# CY8C3246PVI_147 register map
File version: 0.1
CY8C32
Registers are 8-bit, read-write, no defined reset value unless marked. A register's access mark holds for its fields unless they carry their own. Offsets are from the block's base; lines under a group give offsets from that group; [hi:lo] are bit positions; {n}, {i} and the like mark numbered series; 'fields as' and 'values as' point back to an identical list; <NAME> marks a mode.

## Memory map
0x00004382 RTC size 0xF
0x00004394 USBUART size 0x1D0A — USBFS
0x000043AA ADC size 0x17E0
0x0000640A USB_Blink_TI size 0x92
0x0000640C Flash_Blink_TI size 0x92
0x0000640E EEPROM_Blink_TI size 0x92

## RTC
Base 0x00004382
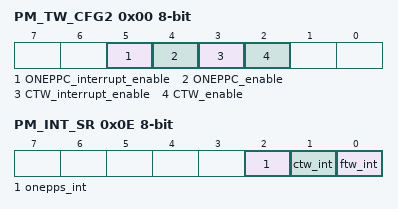
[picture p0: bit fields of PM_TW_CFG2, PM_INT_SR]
0x00 PM_TW_CFG2 — Power timers enable and interrupt enable configuration register
  [5] ONEPPC_interrupt_enable — When set and one pulse-per-second is enabled, an interrupt is issued when the pulse occurs
    1=Enabled (The ONEPPC interrupt is issued. Only if ONEPPC is enabled.); 0=Disabled (No ONEPPC interrupt is issued.)
  [4] ONEPPC_enable
    1=Enabled (The ONEPPC is enabled.); 0=Disabled (The ONEPPC is disabled.)
  [3] CTW_interrupt_enable — An interrupt issue when the CTW reaches the selected interval
    1=Enabled (The CTW interrupt is issued. Only if CTW is enabled.); 0=Disabled (No CTW interrupt is issued.)
  [2] CTW_enable
    1=Enabled (The CTW is enabled.); 0=Disabled (The CTW is disabled.)
0x0E PM_INT_SR — Power Manager Interrupt Status Register
  [2] onepps_int — When set, a onepps event has occured.
  [1] ctw_int — When set, a limited active ready event has occured
  [0] ftw_int — When set, a fast timewheel event has occured

## Flash_Blink_TI
Base 0x0000640C
0x00 Flash_Blink_TI_COUNTER 16-bit — UDB.A0 - Current Down Counter Value
0x20 Flash_Blink_TI_PERIOD 16-bit — UDB.D0 - Assigned Period
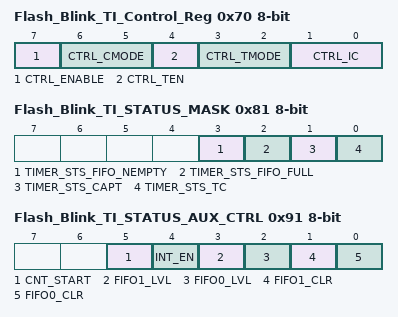
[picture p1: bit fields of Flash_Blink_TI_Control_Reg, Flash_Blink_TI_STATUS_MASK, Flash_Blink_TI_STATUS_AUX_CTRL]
0x70 Flash_Blink_TI_Control_Reg — UDB Control Register - Assigned Control Register Value
  [7] CTRL_ENABLE — Enable the Timer
  [6:5] CTRL_CMODE — Capture Mode
  [4] CTRL_TEN — Trigger Enable Bit
  [3:2] CTRL_TMODE — Trigger Mode
  [1:0] CTRL_IC — Interrupt Count
0x81 Flash_Blink_TI_STATUS_MASK — UDB Status bits Interrupt Mask Enable Register
  [3] TIMER_STS_FIFO_NEMPTY ro — FIFO Empty status
  [2] TIMER_STS_FIFO_FULL ro — FIFO Full Status
  [1] TIMER_STS_CAPT ro — Enables the Interrupt on Capture
  [0] TIMER_STS_TC ro — Enables the Interrupt on TC
0x91 Flash_Blink_TI_STATUS_AUX_CTRL — UDB Auxilliary Control Register
  [5] CNT_START — FIFO0 clear
    0=E_CNT_START0 (Disable counter); 1=E_CNT_START1 (Enable counter)
  [4] INT_EN
    0=E_INT_EN0 (Interrupt disabled); 1=E_INT_EN1 (Interrupt enabled)
  [3] FIFO1_LVL — FIFO level
    0=E_FIFO_LVL_0 (FIFO LVL: input mode: FIFO not full; output mode: FIFO not empty); 1=E_FIFO_LVL_1 (FIFO LVL: input mode: FIFO at least 1/2 empty; output mode: FIFO at least 1/2 full)
  [2] FIFO0_LVL — FIFO level
    values as FIFO1_LVL
  [1] FIFO1_CLR — FIFO1 clear
    0=E_FIFO_CLR_0 (Normal FIFO operation); 1=E_FIFO_CLR_1 (Clear FIFO state)
  [0] FIFO0_CLR — FIFO0 clear
    values as FIFO1_CLR

## USB_Blink_TI
Base 0x0000640A
Registers as Flash_Blink_TI (with Flash_Blink_TI read as USB_Blink_TI), without Flash_Blink_TI_Control_Reg; these are added or differ:
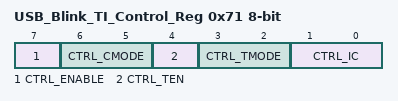
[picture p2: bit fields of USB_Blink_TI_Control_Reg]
0x71 USB_Blink_TI_Control_Reg — UDB Control Register - Assigned Control Register Value
  [7] CTRL_ENABLE — Enable the Timer
  [6:5] CTRL_CMODE — Capture Mode
  [4] CTRL_TEN — Trigger Enable Bit
  [3:2] CTRL_TMODE — Trigger Mode
  [1:0] CTRL_IC — Interrupt Count

## EEPROM_Blink_TI
Base 0x0000640E
Registers as Flash_Blink_TI (with Flash_Blink_TI read as EEPROM_Blink_TI).

## USBUART — USBFS
Base 0x00004394
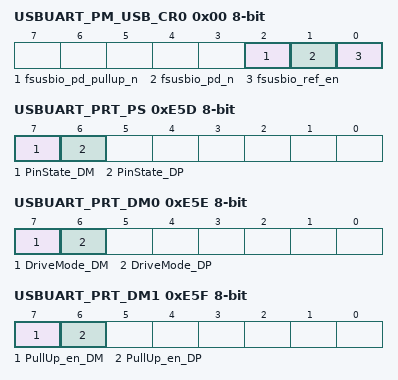
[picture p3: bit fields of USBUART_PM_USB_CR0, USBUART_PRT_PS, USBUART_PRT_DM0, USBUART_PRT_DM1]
0x00 USBUART_PM_USB_CR0 — USB Power Mode Control Register 0
  [2] fsusbio_pd_pullup_n, [1] fsusbio_pd_n, [0] fsusbio_ref_en
0x11 USBUART_PM_ACT_CFG — Active Power Mode Configuration Register
0x21 USBUART_PM_STBY_CFG — Standby Power Mode Configuration Register
0xE5D USBUART_PRT_PS — Port Pin State Register
  [7] PinState_DM ro, [6] PinState_DP ro
0xE5E USBUART_PRT_DM0 — Port Drive Mode Register
  [7] DriveMode_DM, [6] DriveMode_DP
0xE5F USBUART_PRT_DM1 — Port Drive Mode Register
  [7] PullUp_en_DM, [6] PullUp_en_DP
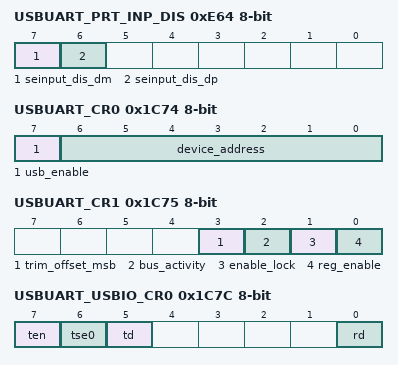
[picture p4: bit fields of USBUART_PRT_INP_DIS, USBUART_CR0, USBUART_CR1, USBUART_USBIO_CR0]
0xE64 USBUART_PRT_INP_DIS — Input buffer disable override
  [7] seinput_dis_dm, [6] seinput_dis_dp
0x1C6C USBUART_EP0_DR0 — bmRequestType
0x1C6D USBUART_EP0_DR1 — bRequest
0x1C6E USBUART_EP0_DR2 — wValueLo
0x1C6F USBUART_EP0_DR3 — wValueHi
0x1C70 USBUART_EP0_DR4 — wIndexLo
0x1C71 USBUART_EP0_DR5 — wIndexHi
0x1C72 USBUART_EP0_DR6 — lengthLo
0x1C73 USBUART_EP0_DR7 — lengthHi
0x1C74 USBUART_CR0 — USB Control Register 0
  [7] usb_enable, [6:0] device_address ro
0x1C75 USBUART_CR1 — USB Control Register 1
  [3] trim_offset_msb, [2] bus_activity, [1] enable_lock, [0] reg_enable
{0x1C6A+0x10*i} USBUART_SIE_EP{i}_CR0 (i=1..8) — The Endpoint{i} Control Register
0x1C7C USBUART_USBIO_CR0 — USBIO Control Register 0
  [7] ten, [6] tse0, [5] td, [0] rd ro
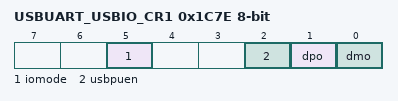
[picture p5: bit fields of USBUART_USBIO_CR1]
0x1C7E USBUART_USBIO_CR1 — USBIO Control Register 1
  [5] iomode, [2] usbpuen, [1] dpo ro, [0] dmo ro
0x1CF8 USBUART_BUF_SIZE — Dedicated Endpoint Buffer Size Register
0x1CFA USBUART_EP_ACTIVE — Endpoint Active Indication Register
0x1CFB USBUART_EP_TYPE — Endpoint Type (IN/OUT) Indication
0x1D09 USBUART_USB_CLK_EN — USB Block Clock Enable Register
